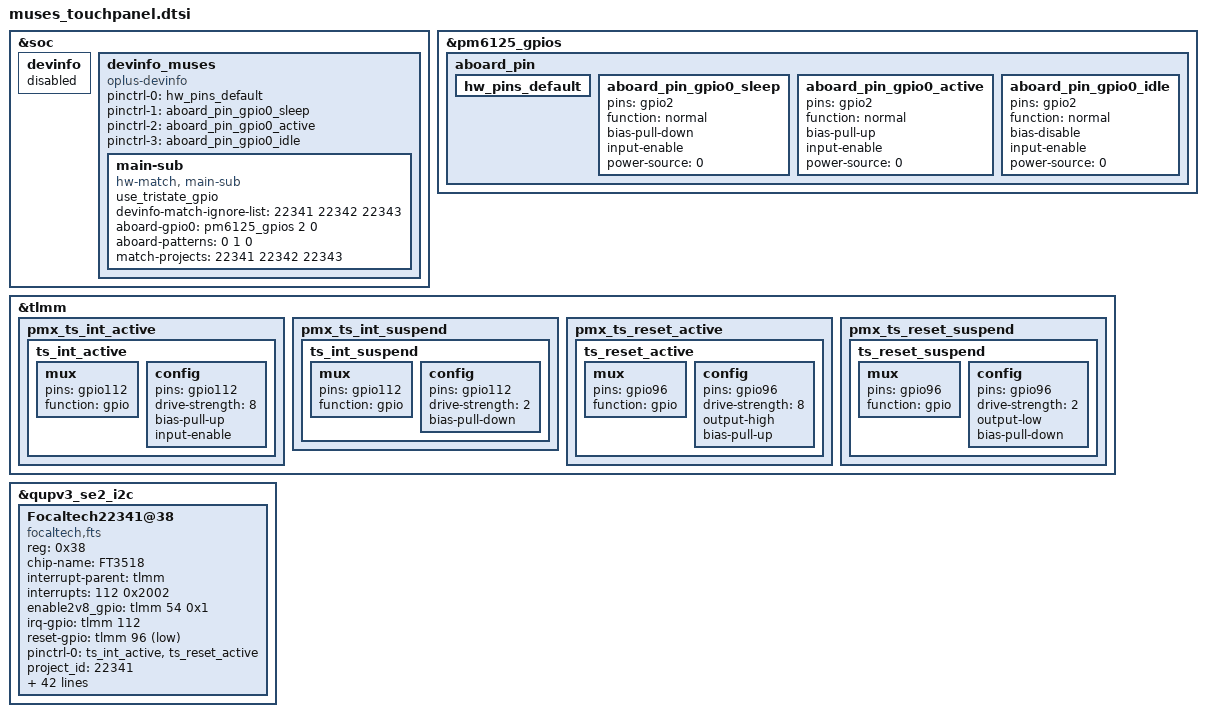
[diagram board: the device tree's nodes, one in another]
&soc {
        devinfo {
                 status = "disabled";
         };
         devinfo_muses {
                 compatible = "oplus-devinfo";

                 pinctrl-names = "default", "sleep", "active", "idle";
                 pinctrl-0 = <&hw_pins_default>;
                 pinctrl-1 = <&aboard_pin_gpio0_sleep>;
                 pinctrl-2 = <&aboard_pin_gpio0_active>;
                 pinctrl-3 = <&aboard_pin_gpio0_idle>;
                 main-sub {
                         use_tristate_gpio;
                        devinfo-match-ignore-list = <22341 22342 22343>;
                         compatible = "hw-match, main-sub";
                         aboard-gpio0 = <&pm6125_gpios 2 0>;
                         aboard-patterns = <0 1 0>;    /*0[high-resistance] 1[pull-down] 2[pull-up]*/
			/*main board*/
                         match-projects = <22341 22342 22343>;
                 };
         };
};

&pm6125_gpios {
         aboard_pin {
                 hw_pins_default:hw_pins_default {
                 };

                 aboard_pin_gpio0_sleep:aboard_pin_gpio0_sleep {
                 pins = "gpio2";
                         function = "normal";
                         bias-pull-down;
                         input-enable;
                         power-source = <0>;
                 };

                 aboard_pin_gpio0_active:aboard_pin_gpio0_active {
                 pins = "gpio2";
                         function = "normal";
                         bias-pull-up;
                         input-enable;
                         power-source = <0>;
                 };

                 aboard_pin_gpio0_idle:aboard_pin_gpio0_idle {
                 pins = "gpio2";
                         function = "normal";
                         bias-disable;
                         input-enable;
                         power-source = <0>;
                 };
         };
};

&tlmm {
	pmx_ts_int_active {
                ts_int_active: ts_int_active {
                        mux {
                                pins = "gpio112";
                                function = "gpio";
                        };

                        config {
                                pins = "gpio112";
                                drive-strength = <8>;
                                bias-pull-up;
                                input-enable;
                        };
                };
        };

        pmx_ts_int_suspend {
                ts_int_suspend: ts_int_suspend {
                        mux {
                                pins = "gpio112";
                                function = "gpio";
                        };

                        config {
                                pins = "gpio112";
                                drive-strength = <2>;
                                bias-pull-down;
                        };
                };
        };

	pmx_ts_reset_active {
                ts_reset_active: ts_reset_active {
                        mux {
                                pins = "gpio96";
                                function = "gpio";
                        };

                        config {
                                pins = "gpio96";
                                drive-strength = <8>;
                                output-high;
                                bias-pull-up;
                        };
                };
        };

        pmx_ts_reset_suspend {
                ts_reset_suspend: ts_reset_suspend {
                        mux {
                                pins = "gpio96";
                                function = "gpio";
                        };

                        config {
                                pins = "gpio96";
                                drive-strength = <2>;
                                output-low;
                                bias-pull-down;
                        };
                };
        };
};

&qupv3_se2_i2c {
        #address-cells = <1>;
        #size-cells = <0>;

        status = "ok";

        Focaltech22341@38 {
                compatible = "focaltech,fts";
                reg = <0x38>;
                chip-name = "FT3518";

                /* Interrupt && Irq-gpio */
                interrupt-parent = <&tlmm>;
                interrupts = <112 0x2002>;

                /* Power Config */
                enable2v8_gpio = <&tlmm 54 0x1>;
                //vdd_2v8_volt = <3008000>;

                /* Other HW Resource */
                irq-gpio = <&tlmm 112 0x2002>;
                reset-gpio = <&tlmm 96 0x1>;
                pinctrl-names = "default";
                pinctrl-0 = <&ts_int_active &ts_reset_active>;

                //vid_len = <2>;
                project_id = <22341>;
                // type of tp_dev ,TP-SAMSUNG = 8;
                panel_type = <8>;
                tp_type = <8>;
                firmware_name = "0xAA31100";
                platform_support_project = <22341 22342 22343>;
                platform_support_project_dir = <22341 22341 22341>;
                platform_support_project_commandline = "default_commandline","default_commandline","default_commandline";
                //platform_support_project_external_name = "AA311", "AA311", "AA311", "AA311", "AA311";

                touchpanel,max-num-support = <10>;
                touchpanel,tx-rx-num = <16 34>;
                touchpanel,panel-coords = <4320 9600>;
                touchpanel,display-coords = <1080 2400>;
                touchpanel,touchmajor-limit = <0 54>;
                touchpanel,report-rate = <120 180>;
                touchpanel,smooth-level = <255 2 15 25 45 60>;
                touchpanel,smooth-level-charging = <255 15 20 25 45 60>;
                touchpanel,sensitive-level = <255 20 16 13 10 5>;
                touchpanel,single-optimized-time = <8>;
                touchpanel,game_perf_para_default = <25 7>;
		touchpanel,irq_need_dev_resume_time = <500>;
		touchpanel,high-frame-rate-time = <60>;
                //prevention,dead_area_width = <20 20>;
                //prevention,condition_area_width = <60 60 160 160>;
                //prevention,eli_area_width = <240 1000 1200 240>;

                /* SW Support Feature Control */
                black_gesture_support;
                black_gesture_indep_support;
                /* sportify_aod_gesture_support; */
                fw_edge_limit_support;
                pressure_report_support;
                charger_pump_support;
                game_switch_support;
                smart_gesture_support;
                fw_update_app_support;
                fingerprint_underscreen_support;
                headset_pump_support;
                irq_need_dev_resume_ok;
                health_monitor_v2_support;
                high_resolution_support;
                esd_handle_support;
                lcd_tp_refresh_support;
                disable_suspend_irq_handler_support;
                exception_upload_support;
                /*
                 *Virtual Key Config:
                 *1:touchpanel,button-type: <virtualkey_type  supportted_button-map>
                 *virtualkey_type:
                 *Type 1: using board_properties
                 *Type 2: using same IC (button zone&& touch zone are seprate)
                 *Type 3: using diffrent IC (button zone&& touch zone are seprate)
                 *Type 4: No need of virtual key process
                 *supportted_button-map:select|menu|home|back
                 *
                 *2:touchpanel,button-map
                 *type (X1,Y1)(X2,Y2)(X3,Y3)(Width_X,Hight_Y)--Only when button-type is 0
                 */
                touchpanel,button-type = <4>;
                touchpanel.button-TRx = <0 0>;
        };
};
